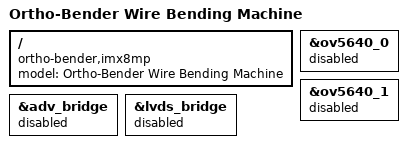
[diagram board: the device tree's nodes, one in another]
// SPDX-License-Identifier: (GPL-2.0+ OR MIT)
/*
 * Device Tree Source for Ortho-Bender Wire Bending Machine
 * Based on NXP i.MX8MP EVK
 *
 * Copyright (C) 2024 Ortho-Bender Project
 *
 * Build target : freescale/imx8mp-ortho-bender.dtb
 * Machine conf : meta-ortho-bender/conf/machine/ortho-bender-imx8mp.conf
 *
 * Subsystem overlays (applied in order):
 *   motors  — TMC260C-PA SPI + M7-reserved GPIO4 pins
 *   sensors — I2C3 sensor expansion bus (Phase 1 placeholder)
 *   camera  — USB3 host for Allied Vision Alvium 1800 U-158m
 *   wifi    — AW-CM358MA SDIO WiFi + UART Bluetooth
 *
 * EVK base provides: HDMI (LCDIF/HDMI-TX), Ethernet (FEC), UART console,
 * eMMC (usdhc3), LPDDR4, and audio codec (WM8960 — depopulated on
 * ortho-bender development builds to free SAI1 pads for motor GPIOs).
 *
 * Author   : Ortho-Bender BSP team
 * SW Class : IEC 62304 Class B
 */

/dts-v1/;

#include "imx8mp-evk.dts"

/ {
	model = "Ortho-Bender Wire Bending Machine";
	compatible = "ortho-bender,imx8mp", "fsl,imx8mp";
};

/* M7 remoteproc — RPMsg virtio transport over MU */
#include "imx8mp-ortho-bender-m7.dtsi"

/* Motor control subsystem — TMC260C-PA x2, M7-reserved GPIO4 */
#include "imx8mp-ortho-bender-motors.dtsi"

/* Sensor expansion bus — I2C3 (Phase 1 placeholder) */
#include "imx8mp-ortho-bender-sensors.dtsi"

/* Camera subsystem — USB3 host for Alvium 1800 U-158m */
#include "imx8mp-ortho-bender-camera.dtsi"

/* WiFi/BT subsystem — AW-CM358MA SDIO + UART */
#include "imx8mp-ortho-bender-wifi.dtsi"

/*
 * Disable unused EVK peripherals to suppress probe errors.
 * Ortho-Bender is headless (no display) and uses Allied Vision USB3
 * camera instead of EVK OV5640 MIPI-CSI.
 */

/* EVK OV5640 MIPI-CSI cameras — not used (Allied Vision Alvium via USB3) */
&ov5640_0 {
	status = "disabled";
};

&ov5640_1 {
	status = "disabled";
};

/* HDMI bridge — headless device, no display output */
&adv_bridge {
	status = "disabled";
};

/* LVDS-to-HDMI bridge (IT6263) — headless device, no display output */
&lvds_bridge {
	status = "disabled";
};
